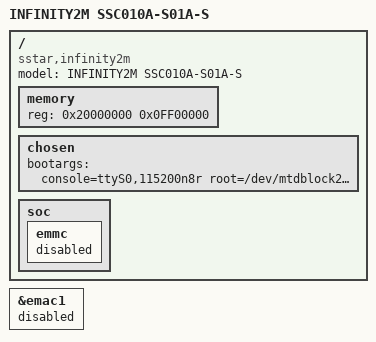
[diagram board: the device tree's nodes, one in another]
/*
 * infinity2m-ssc010a-nvr.dts - SSR621Q NVRs (SSC010A board), for OpenIPC
 *
 * Based on the SigmaStar SSC010A-S01A board; matches what the Xiongmai
 * NBD80S16S NVR ships: one EMAC (internal PHY), no eMMC.
 */

/dts-v1/;
#include "infinity2m.dtsi"
#include "infinity2m-ssc010a-s01a.dtsi"
#include "infinity2m-ssc010a-s01a-padmux.dtsi"

/ {
    model = "INFINITY2M SSC010A-S01A-S";
    compatible = "sstar,infinity2m";

    /* replaced by LX_MEM */
    memory {
        reg = <0x20000000 0x0FF00000>;
    };

    chosen {
        bootargs = "console=ttyS0,115200n8r root=/dev/mtdblock2 init=/linuxrc";
    };

    soc {
        emmc {
            status = "disabled";
        };
    };
};

&emac1 {
    status = "disabled";
};
